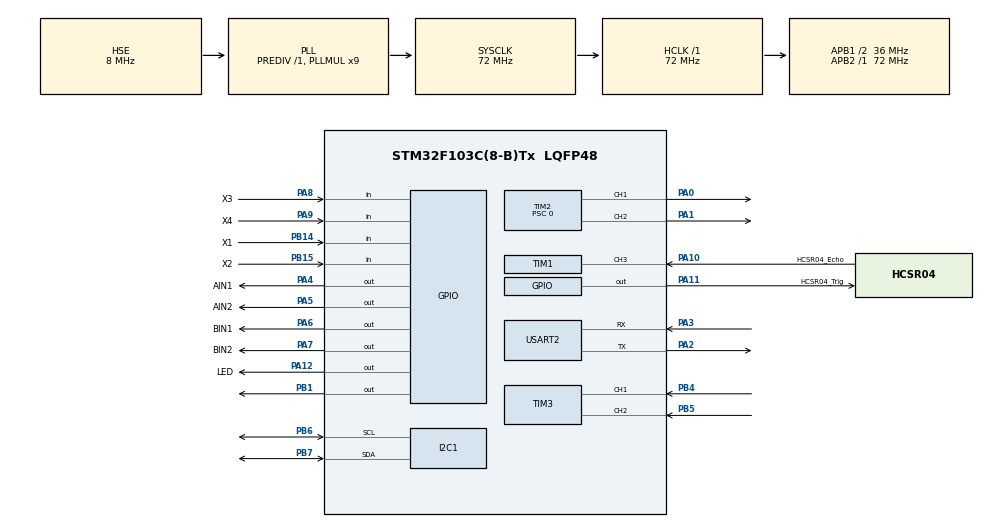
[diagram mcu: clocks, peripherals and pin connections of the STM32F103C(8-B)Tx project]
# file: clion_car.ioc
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FREERTOS.BinarySemaphores01=EchoBinarySem,Dynamic,NULL,Depleted
FREERTOS.Queues01=LEDFlash,16,uint32_t,0,Dynamic,NULL,NULL;Distance,16,float,0,Dynamic,NULL,NULL;Track,16,uint8_t,0,Dynamic,NULL,NULL;DriverPWM,16,uint32_t,0,Dynamic,NULL,NULL;MotorAction,16,uint64_t,0,Dynamic,NULL,NULL
FREERTOS.Tasks01=LedTask,8,128,StartLedTask,As weak,NULL,Dynamic,NULL,NULL;UartTask,8,160,StartUartTask,As external,NULL,Dynamic,NULL,NULL;OledTask,8,160,StartOledTask,As external,NULL,Dynamic,NULL,NULL;HCSR04Task,48,256,StartHCSR04Task,As external,NULL,Dynamic,NULL,NULL;TrackTask,25,128,StartTrackTask,As external,NULL,Dynamic,NULL,NULL;DriverTask,32,128,StartDriverTask,As external,NULL,Dynamic,NULL,NULL;CtrlTask,24,128,StartCtrlTask,As external,NULL,Dynamic,NULL,NULL
FREERTOS.configTOTAL_HEAP_SIZE=8192
I2C1.I2C_Mode=I2C_Fast
Mcu.Family=STM32F1
Mcu.Name=STM32F103C(8-B)Tx
Mcu.Package=LQFP48
NVIC.PriorityGroup=NVIC_PRIORITYGROUP_4
NVIC.TIM1_CC_IRQn=true\:5\:0\:true\:false\:true\:true\:true\:true\:true
NVIC.TIM4_IRQn=true\:15\:0\:false\:false\:true\:false\:false\:true\:true
NVIC.TimeBase=TIM4_IRQn
NVIC.TimeBaseIP=TIM4
PA0-WKUP.Signal=S_TIM2_CH1_ETR
PA1.Signal=S_TIM2_CH2
PA10.GPIO_Label=HCSR04_Echo
PA10.Signal=S_TIM1_CH3
PA11.GPIO_Label=HCSR04_Trig
PA11.Signal=GPIO_Output
PA12.GPIO_Label=LED
PA12.PinState=GPIO_PIN_SET
PA12.Signal=GPIO_Output
PA13.Mode=Serial_Wire
PA13.Signal=SYS_JTMS-SWDIO
PA14.Mode=Serial_Wire
PA14.Signal=SYS_JTCK-SWCLK
PA2.Mode=Asynchronous
PA2.Signal=USART2_TX
PA3.Mode=Asynchronous
PA3.Signal=USART2_RX
PA4.GPIO_Label=AIN1
PA4.Signal=GPIO_Output
PA5.GPIO_Label=AIN2
PA5.Signal=GPIO_Output
PA6.GPIO_Label=BIN1
PA6.Signal=GPIO_Output
PA7.GPIO_Label=BIN2
PA7.Signal=GPIO_Output
PA8.GPIO_Label=X3
PA8.Signal=GPIO_Input
PA9.GPIO_Label=X4
PA9.Signal=GPIO_Input
PB1.Signal=GPIO_Output
PB14.GPIO_Label=X1
PB14.Signal=GPIO_Input
PB15.GPIO_Label=X2
PB15.Signal=GPIO_Input
PB4.Signal=S_TIM3_CH1
PB5.Signal=S_TIM3_CH2
PB6.Mode=I2C
PB6.Signal=I2C1_SCL
PB7.Mode=I2C
PB7.Signal=I2C1_SDA
PD0-OSC_IN.Mode=HSE-External-Oscillator
PD0-OSC_IN.Signal=RCC_OSC_IN
PD1-OSC_OUT.Mode=HSE-External-Oscillator
PD1-OSC_OUT.Signal=RCC_OSC_OUT
ProjectManager.HeapSize=0x200
ProjectManager.StackSize=0x400
ProjectManager.TargetToolchain=CMake
RCC.AHBFreq_Value=72000000
RCC.APB1CLKDivider=RCC_HCLK_DIV2
RCC.APB1Freq_Value=36000000
RCC.APB1TimFreq_Value=72000000
RCC.APB2Freq_Value=72000000
RCC.APB2TimFreq_Value=72000000
RCC.HCLKFreq_Value=72000000
RCC.PLLMUL=RCC_PLL_MUL9
RCC.PLLSourceVirtual=RCC_PLLSOURCE_HSE
RCC.SYSCLKFreq_VALUE=72000000
RCC.SYSCLKSource=RCC_SYSCLKSOURCE_PLLCLK
RCC.USBFreq_Value=72000000
SH.S_TIM1_CH3.0=TIM1_CH3,Input_Capture3_from_TI3
SH.S_TIM2_CH1_ETR.0=TIM2_CH1,PWM Generation1 CH1
SH.S_TIM2_CH2.0=TIM2_CH2,PWM Generation2 CH2
SH.S_TIM3_CH1.0=TIM3_CH1,Encoder_Interface
SH.S_TIM3_CH2.0=TIM3_CH2,Encoder_Interface
TIM1.Channel-Input_Capture3_from_TI3=TIM_CHANNEL_3
TIM1.ICPolarity_CH3=TIM_INPUTCHANNELPOLARITY_RISING
TIM1.Prescaler=71
TIM2.Channel-PWM\ Generation1\ CH1=TIM_CHANNEL_1
TIM2.Channel-PWM\ Generation2\ CH2=TIM_CHANNEL_2
TIM2.Period=999
TIM2.Prescaler=0
TIM3.EncoderMode=TIM_ENCODERMODE_TI12
TIM3.IC1Filter=15
TIM3.IC2Filter=15
USART2.VirtualMode=VM_ASYNC
VP_FREERTOS_VS_CMSIS_V2.Mode=CMSIS_V2
VP_SYS_VS_tim4.Mode=TIM4
VP_TIM1_VS_ClockSourceINT.Mode=Internal
VP_TIM2_VS_ClockSourceINT.Mode=Internal
board=custom

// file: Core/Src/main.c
/* USER CODE BEGIN Header */
/**
  ******************************************************************************
  * @file           : main.c
  * @brief          : Main program body
  ******************************************************************************
  * @attention
  *
  * Copyright (c) 2026 STMicroelectronics.
  * All rights reserved.
  *
  * This software is licensed under terms that can be found in the LICENSE file
  * in the root directory of this software component.
  * If no LICENSE file comes with this software, it is provided AS-IS.
  *
  ******************************************************************************
  */
/* USER CODE END Header */
#include "main.h"
#include "cmsis_os.h"
#include "i2c.h"
#include "tim.h"
#include "usart.h"
#include "gpio.h"

void SystemClock_Config(void);
void MX_FREERTOS_Init(void);

int main(void)
{

  /* MCU Configuration--------------------------------------------------------*/

  /* Reset of all peripherals, Initializes the Flash interface and the Systick. */
  HAL_Init();

  /* Configure the system clock */
  SystemClock_Config();

  /* Initialize all configured peripherals */
  MX_GPIO_Init();
  MX_I2C1_Init();
  MX_USART2_UART_Init();
  MX_TIM1_Init();
  MX_TIM2_Init();
  MX_TIM3_Init();

  /* Init scheduler */
  osKernelInitialize();  /* Call init function for freertos objects (in cmsis_os2.c) */
  MX_FREERTOS_Init();

  /* Start scheduler */
  osKernelStart();

  /* We should never get here as control is now taken by the scheduler */

  /* Infinite loop */
  while (1)
  {

  }
}

void SystemClock_Config(void)
{
  RCC_OscInitTypeDef RCC_OscInitStruct = {0};
  RCC_ClkInitTypeDef RCC_ClkInitStruct = {0};

  /** Initializes the RCC Oscillators according to the specified parameters
  * in the RCC_OscInitTypeDef structure.
  */
  RCC_OscInitStruct.OscillatorType = RCC_OSCILLATORTYPE_HSE;
  RCC_OscInitStruct.HSEState = RCC_HSE_ON;
  RCC_OscInitStruct.HSEPredivValue = RCC_HSE_PREDIV_DIV1;
  RCC_OscInitStruct.HSIState = RCC_HSI_ON;
  RCC_OscInitStruct.PLL.PLLState = RCC_PLL_ON;
  RCC_OscInitStruct.PLL.PLLSource = RCC_PLLSOURCE_HSE;
  RCC_OscInitStruct.PLL.PLLMUL = RCC_PLL_MUL9;
  if (HAL_RCC_OscConfig(&RCC_OscInitStruct) != HAL_OK)
  {
    Error_Handler();
  }

  /** Initializes the CPU, AHB and APB buses clocks
  */
  RCC_ClkInitStruct.ClockType = RCC_CLOCKTYPE_HCLK|RCC_CLOCKTYPE_SYSCLK
                              |RCC_CLOCKTYPE_PCLK1|RCC_CLOCKTYPE_PCLK2;
  RCC_ClkInitStruct.SYSCLKSource = RCC_SYSCLKSOURCE_PLLCLK;
  RCC_ClkInitStruct.AHBCLKDivider = RCC_SYSCLK_DIV1;
  RCC_ClkInitStruct.APB1CLKDivider = RCC_HCLK_DIV2;
  RCC_ClkInitStruct.APB2CLKDivider = RCC_HCLK_DIV1;

  if (HAL_RCC_ClockConfig(&RCC_ClkInitStruct, FLASH_LATENCY_2) != HAL_OK)
  {
    Error_Handler();
  }
}

void HAL_TIM_PeriodElapsedCallback(TIM_HandleTypeDef *htim)
{
  if (htim->Instance == TIM4)
  {
    HAL_IncTick();
  }
}

void Error_Handler(void)
{
  __disable_irq();
  while (1)
  {
  }
}

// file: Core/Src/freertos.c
/* USER CODE BEGIN Header */
/**
  ******************************************************************************
  * File Name          : freertos.c
  * Description        : Code for freertos applications
  ******************************************************************************
  * @attention
  *
  * Copyright (c) 2026 STMicroelectronics.
  * All rights reserved.
  *
  * This software is licensed under terms that can be found in the LICENSE file
  * in the root directory of this software component.
  * If no LICENSE file comes with this software, it is provided AS-IS.
  *
  ******************************************************************************
  */
/* USER CODE END Header */

#include "FreeRTOS.h"
#include "task.h"
#include "main.h"
#include "cmsis_os.h"

/* Definitions for LedTask */
osThreadId_t LedTaskHandle;
const osThreadAttr_t LedTask_attributes = {
  .name = "LedTask",
  .stack_size = 128 * 4,
  .priority = (osPriority_t) osPriorityLow,
};
/* Definitions for UartTask */
osThreadId_t UartTaskHandle;
const osThreadAttr_t UartTask_attributes = {
  .name = "UartTask",
  .stack_size = 160 * 4,
  .priority = (osPriority_t) osPriorityLow,
};
/* Definitions for OledTask */
osThreadId_t OledTaskHandle;
const osThreadAttr_t OledTask_attributes = {
  .name = "OledTask",
  .stack_size = 160 * 4,
  .priority = (osPriority_t) osPriorityLow,
};
/* Definitions for HCSR04Task */
osThreadId_t HCSR04TaskHandle;
const osThreadAttr_t HCSR04Task_attributes = {
  .name = "HCSR04Task",
  .stack_size = 256 * 4,
  .priority = (osPriority_t) osPriorityRealtime,
};
/* Definitions for TrackTask */
osThreadId_t TrackTaskHandle;
const osThreadAttr_t TrackTask_attributes = {
  .name = "TrackTask",
  .stack_size = 128 * 4,
  .priority = (osPriority_t) osPriorityNormal1,
};
/* Definitions for DriverTask */
osThreadId_t DriverTaskHandle;
const osThreadAttr_t DriverTask_attributes = {
  .name = "DriverTask",
  .stack_size = 128 * 4,
  .priority = (osPriority_t) osPriorityAboveNormal,
};
/* Definitions for CtrlTask */
osThreadId_t CtrlTaskHandle;
const osThreadAttr_t CtrlTask_attributes = {
  .name = "CtrlTask",
  .stack_size = 128 * 4,
  .priority = (osPriority_t) osPriorityNormal,
};
/* Definitions for LEDFlash */
osMessageQueueId_t LEDFlashHandle;
const osMessageQueueAttr_t LEDFlash_attributes = {
  .name = "LEDFlash"
};
/* Definitions for Distance */
osMessageQueueId_t DistanceHandle;
const osMessageQueueAttr_t Distance_attributes = {
  .name = "Distance"
};
/* Definitions for Track */
osMessageQueueId_t TrackHandle;
const osMessageQueueAttr_t Track_attributes = {
  .name = "Track"
};
/* Definitions for DriverPWM */
osMessageQueueId_t DriverPWMHandle;
const osMessageQueueAttr_t DriverPWM_attributes = {
  .name = "DriverPWM"
};
/* Definitions for MotorAction */
osMessageQueueId_t MotorActionHandle;
const osMessageQueueAttr_t MotorAction_attributes = {
  .name = "MotorAction"
};
/* Definitions for EchoBinarySem */
osSemaphoreId_t EchoBinarySemHandle;
const osSemaphoreAttr_t EchoBinarySem_attributes = {
  .name = "EchoBinarySem"
};

void StartLedTask(void *argument);
extern void StartUartTask(void *argument);
extern void StartOledTask(void *argument);
extern void StartHCSR04Task(void *argument);
extern void StartTrackTask(void *argument);
extern void StartDriverTask(void *argument);
extern void StartCtrlTask(void *argument);

void MX_FREERTOS_Init(void); /* (MISRA C 2004 rule 8.1) */

void MX_FREERTOS_Init(void) {

  /* Create the semaphores(s) */
  /* creation of EchoBinarySem */
  EchoBinarySemHandle = osSemaphoreNew(1, 0, &EchoBinarySem_attributes);

  /* USER CODE BEGIN RTOS_SEMAPHORES */
  /* add semaphores, ... */
  EchoBinarySemHandle = osSemaphoreNew(1, 0, &EchoBinarySem_attributes);
  /* USER CODE END RTOS_SEMAPHORES */

  /* Create the queue(s) */
  /* creation of LEDFlash */
  LEDFlashHandle = osMessageQueueNew (16, sizeof(uint32_t), &LEDFlash_attributes);

  /* creation of Distance */
  DistanceHandle = osMessageQueueNew (16, sizeof(float), &Distance_attributes);

  /* creation of Track */
  TrackHandle = osMessageQueueNew (16, sizeof(uint8_t), &Track_attributes);

  /* creation of DriverPWM */
  DriverPWMHandle = osMessageQueueNew (16, sizeof(uint32_t), &DriverPWM_attributes);

  /* creation of MotorAction */
  MotorActionHandle = osMessageQueueNew (16, sizeof(uint64_t), &MotorAction_attributes);

  /* Create the thread(s) */
  /* creation of LedTask */
  LedTaskHandle = osThreadNew(StartLedTask, NULL, &LedTask_attributes);

  /* creation of UartTask */
  UartTaskHandle = osThreadNew(StartUartTask, NULL, &UartTask_attributes);

  /* creation of OledTask */
  OledTaskHandle = osThreadNew(StartOledTask, NULL, &OledTask_attributes);

  /* creation of HCSR04Task */
  HCSR04TaskHandle = osThreadNew(StartHCSR04Task, NULL, &HCSR04Task_attributes);

  /* creation of TrackTask */
  TrackTaskHandle = osThreadNew(StartTrackTask, NULL, &TrackTask_attributes);

  /* creation of DriverTask */
  DriverTaskHandle = osThreadNew(StartDriverTask, NULL, &DriverTask_attributes);

  /* creation of CtrlTask */
  CtrlTaskHandle = osThreadNew(StartCtrlTask, NULL, &CtrlTask_attributes);

}

__weak void StartLedTask(void *argument)
{
  for(;;)
  {
    osDelay(1);
  }
}
